# GD32F5xx register map
File version: 1.0
CPU: CM33 r0p1, little endian, MPU, FPU, 4 interrupt priority bits
Registers are 32-bit, read-write, reset 0x0 unless marked. A register's access mark holds for its fields unless they carry their own. Offsets are from the block's base; [hi:lo] are bit positions; {n}, {i} and the like mark numbered series.

## FMC — Flash memory controller
Base 0x40023C00
0x04 KEY wo — Unlock key register
  [31:0] KEY — FMC_CTL unlock register
0x08 OBKEY wo — Option byte unlock key register
  [31:0] OBKEY — FMC_OBCTLx option byte operation unlock register
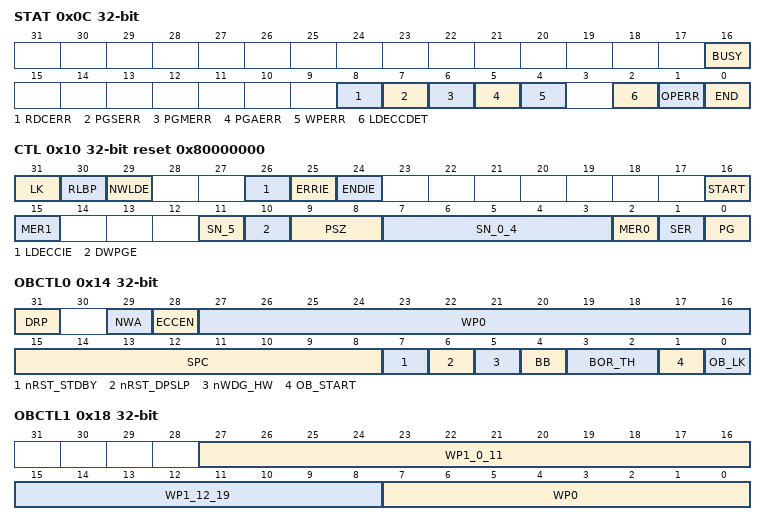
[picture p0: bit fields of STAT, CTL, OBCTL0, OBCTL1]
0x0C STAT access per field — Status register
  [16] BUSY ro — The flash is busy bit.
  [8] RDCERR rw — Read CBUS protection error flag bit.
  [7] PGSERR rw — Program sequence error flag bit.
  [6] PGMERR rw — Program size not match error flag bit.
  [5] PGAERR rw — Program alignment error flag bit
  [4] WPERR rw — Erase/Program protection error flag bit.
  [2] LDECCDET rw — Two bits ECC error flag bit when load code.
  [1] OPERR rw — Flash operation error flag bit.
  [0] END rw — End of operation flag bit.
0x10 CTL access per field reset 0x80000000 — Control register
  [31] LK rw — FMC_CTL lock bit
  [30] RLBP wo — Read lock block protection for OTP2.
  [29] NWLDE rw — Enable no wait time area load when system reset. This bit is only restored by power on reset.
  [26] LDECCIE rw — Load code ECC error interrupt enable bit.
  [25] ERRIE rw — Error interrupt enable bit.
  [24] ENDIE rw — End of operation interrupt enable bit.
  [16] START rw — send erase command to FMC bit.
  [15] MER1 rw — main flash mass erase for bank1command bit.
  [11] SN_5 rw — Refer to SN[4:0].
  [10] DWPGE rw — Double word program size bit enable.
  [9:8] PSZ rw — Program size bit when DWPGE=0.
  [7:3] SN_0_4 rw — Select which sector number to be erased.
  [2] MER0 rw — main flash mass erase for bank0 command bit.
  [1] SER rw — main flash sector erase command bit.
  [0] PG rw — main flash program command bit.
0x14 OBCTL0 — Option byte control register 0
  [31] DRP — CBUS data read protection bit.
  [29] NWA — Select no wait time area.
  [28] ECCEN — ECC enable bit.
  [27:16] WP0 — Erase/program protection of each sector when DRP is 0.
  [15:8] SPC — option byte security protection code.
  [7] nRST_STDBY — option byte standby reset value.
  [6] nRST_DPSLP — option byte deepsleep reset value.
  [5] nWDG_HW — option byte watchdog value.
  [4] BB — option byte boot bank value.
  [3:2] BOR_TH — option byte BOR threshold value.
  [1] OB_START — send option byte change command to FMC bit.
  [0] OB_LK — FMC_OBCTLx lock bit
0x18 OBCTL1 — Option byte control register 1
  [27:16] WP1_0_11 — Erase/program protection of each sector when DRP is 0
  [15:8] WP1_12_19 — Erase/program protection of each sector when DRP is 0
  [7:0] WP0 — Erase/program protection of each sector when DRP is 0
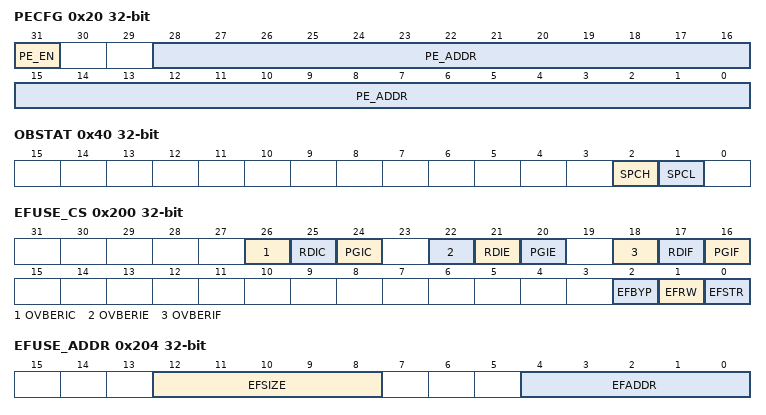
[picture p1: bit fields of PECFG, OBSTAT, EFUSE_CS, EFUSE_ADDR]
0x20 PECFG — Page erase configuration register
  [31] PE_EN — The enable bit of page erase function
  [28:0] PE_ADDR — Page address (4KB alignment).
0x24 PEKEY wo — Unlock page erase key register
  [31:0] PE_KEY — FMC_PECFG unlock register
0x28 OTP1CFG reset 0xFFFF — OTP1 configuration register
  [15:0] OTP1REN — OTP1 read enable.
{0x2C+4i} LDECCADDR{i} reset 0xFFFFFFFF (i=0..2) — Load code ECC error address{i}
  [31:0] LDECCADDR{i} — ECC two bits error base address (aligned to 64bit) when load code from main flash / bootloader OTP1. Any bits in 64bit may be wrong.
0x40 OBSTAT ro — Option bytes status register
  [2] SPCH — Security protection is level high now.
  [1] SPCL — Security protection is level low now.
0x100 PID ro — Product ID register
  [31:0] PID — Product reserved ID code register
0x200 EFUSE_CS access per field — Efuse control and status register
  [26] OVBERIC rw — Clear bit for overstep boundary error interrupt flag.
  [25] RDIC rw — Clear bit for read operation completed interrupt flag.
  [24] PGIC rw — Clear bit for program operation completed interrupt flag.
  [22] OVBERIE rw — Enable bit for overstep boundary error interrupt.
  [21] RDIE rw — Enable bit for read operation completed interrupt.
  [20] PGIE rw — Enable bit for program operation completed interrupt.
  [18] OVBERIF ro — Overstep boundary error flag.
  [17] RDIF ro — Read operation complete flag.
  [16] PGIF ro — Program operation completed flag.
  [2] EFBYP rw — Efuse LDO bypass. This bit can be set only when EFSTR is 0. And users should make sure the external voltage supply is stable before seting EFSTR if set this bit. The program voltage should whitin 2.25V~2.75V. And typical voltage is 2.5V.
  [1] EFRW rw — The selection of efuse operation.
  [0] EFSTR rw — Start efuse operation.
0x204 EFUSE_ADDR — Efuse address register
  [12:8] EFSIZE — Read or write efuse data size.
  [4:0] EFADDR — Read or write efuse data start address.
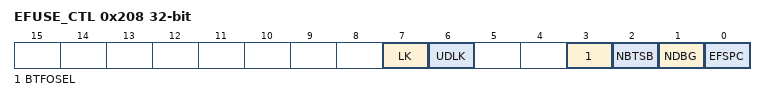
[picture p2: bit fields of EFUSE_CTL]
0x208 EFUSE_CTL — Efuse control register
  [7] LK — EFUSE_CTL register lock bit.
  [6] UDLK — EFUSE_USER_DATA register lock bit
  [3] BTFOSEL — Select Boot from flash or OTP1. This bit actives when NBTSB is 1 or BOOT0 is 0.
  [2] NBTSB — Not boot from SRAM or bootloader.
  [1] NDBG — Debugging permission setting.
  [0] EFSPC — Efuse Security protection. Forbid SPC from no protect to level low.
0x20C EFUSE_USER_DATA
  [7:0] USERDATA — Efuse USER_DATA value.
